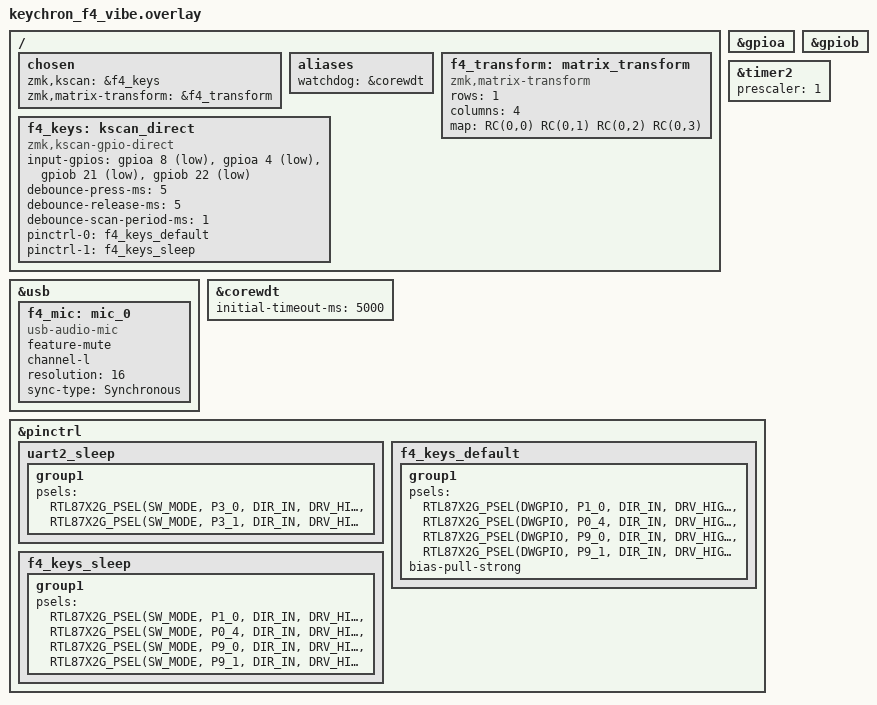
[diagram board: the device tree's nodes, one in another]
#include <zephyr/dt-bindings/gpio/gpio.h>
#include <zephyr/dt-bindings/pinctrl/rtl87x2g-pinctrl.h>
#include <dt-bindings/zmk/matrix_transform.h>

&gpioa {
    status = "okay";
};

&gpiob {
    status = "okay";
};

&usb {
    status = "okay";

    f4_mic: mic_0 {
        compatible = "usb-audio-mic";
        feature-mute;
        channel-l;
        resolution = <16>;
        sync-type = "Synchronous";
    };
};

&timer2 {
    status = "okay";
    prescaler = <1>;
};

&corewdt {
    status = "okay";
    initial-timeout-ms = <5000>;
};

/ {
    chosen {
        zmk,kscan = &f4_keys;
        zmk,matrix-transform = &f4_transform;
    };

    aliases {
        watchdog = &corewdt;
    };

    f4_transform: matrix_transform {
        compatible = "zmk,matrix-transform";
        rows = <1>;
        columns = <4>;
        map = <RC(0,0) RC(0,1) RC(0,2) RC(0,3)>;
    };

    f4_keys: kscan_direct {
        compatible = "zmk,kscan-gpio-direct";
        input-gpios =
            <&gpioa 8  (GPIO_ACTIVE_LOW | GPIO_PULL_UP)>,  /* P1_0, key 1 */
            <&gpioa 4  (GPIO_ACTIVE_LOW | GPIO_PULL_UP)>,  /* P0_4, key 2 */
            <&gpiob 21 (GPIO_ACTIVE_LOW | GPIO_PULL_UP)>,  /* P9_0, key 3 */
            <&gpiob 22 (GPIO_ACTIVE_LOW | GPIO_PULL_UP)>;  /* P9_1, key 4 */
        debounce-press-ms = <5>;
        debounce-release-ms = <5>;
        debounce-scan-period-ms = <1>;
        pinctrl-0 = <&f4_keys_default>;
        pinctrl-1 = <&f4_keys_sleep>;
        pinctrl-names = "default", "sleep";
    };
};

&pinctrl {
    uart2_sleep: uart2_sleep {
        group1 {
            psels =
                <RTL87X2G_PSEL(SW_MODE, P3_0, DIR_IN, DRV_HIGH, PULL_UP)>,
                <RTL87X2G_PSEL(SW_MODE, P3_1, DIR_IN, DRV_HIGH, PULL_UP)>;
        };
    };

    f4_keys_default: f4_keys_default {
        group1 {
            psels =
                <RTL87X2G_PSEL(DWGPIO, P1_0, DIR_IN, DRV_HIGH, PULL_UP)>,
                <RTL87X2G_PSEL(DWGPIO, P0_4, DIR_IN, DRV_HIGH, PULL_UP)>,
                <RTL87X2G_PSEL(DWGPIO, P9_0, DIR_IN, DRV_HIGH, PULL_UP)>,
                <RTL87X2G_PSEL(DWGPIO, P9_1, DIR_IN, DRV_HIGH, PULL_UP)>;
            bias-pull-strong;
        };
    };

    f4_keys_sleep: f4_keys_sleep {
        group1 {
            psels =
                <RTL87X2G_PSEL(SW_MODE, P1_0, DIR_IN, DRV_HIGH, PULL_UP)>,
                <RTL87X2G_PSEL(SW_MODE, P0_4, DIR_IN, DRV_HIGH, PULL_UP)>,
                <RTL87X2G_PSEL(SW_MODE, P9_0, DIR_IN, DRV_HIGH, PULL_UP)>,
                <RTL87X2G_PSEL(SW_MODE, P9_1, DIR_IN, DRV_HIGH, PULL_UP)>;
        };
    };
};
